AUTOSAR XML (schema 00049)
package /ISOFT/PlatformComponents/idsm
  process design idsm_daemon_design: executable=idsmd
package /ISOFT/PlatformComponents/idsm/exe
  executable idsmd: build-type=BUILD-TYPE-RELEASE, logging-behavior=USES-LOGGING, minimum-timer-granularity=0.2, reporting-behavior=REPORTS-EXECUTION-STATE, version=1.0.0
    root sw component prototype rootSwComponentPrototype_idsmd: application-type=swComponent_idsm
package /ISOFT/PlatformComponents/idsm/swc
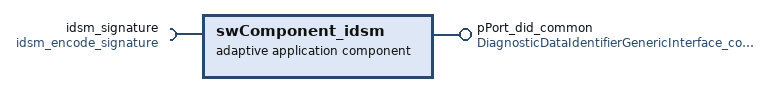
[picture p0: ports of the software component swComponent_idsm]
  adaptive application sw component type swComponent_idsm
    require port idsm_signature: required-interface=idsm_encode_signature
    provide port pPort_did_common: provided-interface=DiagnosticDataIdentifierGenericInterface_common
    adaptive swc internal behavior AdaptiveSwcInternalBehavior
      swc service dependency DiagnosticDataIdentifierGeneric_idsm_common: assigned-ports=role-based-port-assignment={port-prototype=pPort_did_common, role=DiagnosticDataIdentifierGenericInterface}
        service-needs:
          diagnostic value needs DiagnosticValueNeeds: diagnostic-value-access=READ-WRITE
